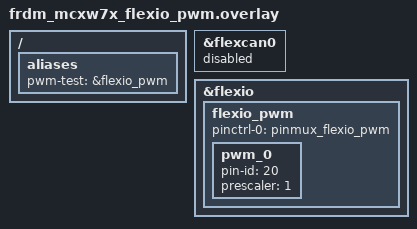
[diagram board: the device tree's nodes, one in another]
/*
 * Copyright 2025 NXP
 *
 * SPDX-License-Identifier: Apache-2.0
 */

/ {
	aliases {
		pwm-test = &flexio_pwm;
	};
};

/* Conflicting gpio pins */
&flexcan0 {
	status = "disabled";
};

&flexio {
	status = "okay";

	flexio_pwm: flexio_pwm {
		pinctrl-0 = <&pinmux_flexio_pwm>;
		pinctrl-names = "default";
		status = "okay";

		pwm_0 {
			pin-id = <20>;
			prescaler = <1>;
		};
	};
};
